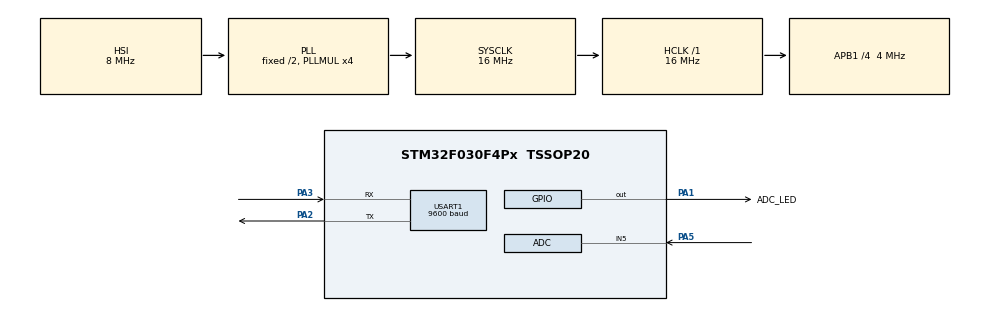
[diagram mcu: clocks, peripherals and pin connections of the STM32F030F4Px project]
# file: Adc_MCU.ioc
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ADC.ClockPrescaler=ADC_CLOCK_ASYNC_DIV1
ADC.ContinuousConvMode=DISABLE
ADC.DMAContinuousRequests=ENABLE
ADC.ExternalTrigConv=ADC_EXTERNALTRIGCONV_T3_TRGO
ADC.SamplingTime=ADC_SAMPLETIME_239CYCLES_5
Dma.ADC.0.Direction=DMA_PERIPH_TO_MEMORY
Dma.ADC.0.Instance=DMA1_Channel1
Dma.ADC.0.MemDataAlignment=DMA_MDATAALIGN_HALFWORD
Dma.ADC.0.MemInc=DMA_MINC_ENABLE
Dma.ADC.0.Mode=DMA_CIRCULAR
Dma.ADC.0.PeriphDataAlignment=DMA_PDATAALIGN_HALFWORD
Dma.ADC.0.PeriphInc=DMA_PINC_DISABLE
Dma.ADC.0.Priority=DMA_PRIORITY_MEDIUM
Dma.Request0=ADC
Mcu.Family=STM32F0
Mcu.Name=STM32F030F4Px
Mcu.Package=TSSOP20
NVIC.DMA1_Channel1_IRQn=true\:0\:0\:false\:false\:true\:false\:true
NVIC.TIM3_IRQn=true\:0\:0\:false\:false\:true\:true\:true
PA1.GPIO_Label=ADC_LED
PA1.Signal=GPIO_Output
PA13.Mode=Serial_Wire
PA13.Signal=SYS_SWDIO
PA14.Mode=Serial_Wire
PA14.Signal=SYS_SWCLK
PA2.Mode=Asynchronous
PA2.Signal=USART1_TX
PA3.Mode=Asynchronous
PA3.Signal=USART1_RX
PA5.Mode=IN5
PA5.Signal=ADC_IN5
ProjectManager.HeapSize=0x200
ProjectManager.StackSize=0x400
ProjectManager.TargetToolchain=STM32CubeIDE
RCC.AHBFreq_Value=16000000
RCC.APB1CLKDivider=RCC_HCLK_DIV4
RCC.APB1Freq_Value=4000000
RCC.APB1TimFreq_Value=8000000
RCC.HCLKFreq_Value=16000000
RCC.PLLMUL=RCC_PLL_MUL4
RCC.SYSCLKFreq_VALUE=16000000
RCC.SYSCLKSource=RCC_SYSCLKSOURCE_PLLCLK
TIM3.Period=1
TIM3.Prescaler=7999
TIM3.TIM_MasterOutputTrigger=TIM_TRGO_UPDATE
USART1.BaudRate=9600
USART1.Mode=MODE_TX
USART1.VirtualMode-Asynchronous=VM_ASYNC
VP_TIM3_VS_ClockSourceINT.Mode=Internal
board=custom

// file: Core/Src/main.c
/* USER CODE BEGIN Header */
/**
  ******************************************************************************
  * @file           : main.c
  * @brief          : Main program body
  ******************************************************************************
  * @attention
  *
  * Copyright (c) 2022 STMicroelectronics.
  * All rights reserved.
  *
  * This software is licensed under terms that can be found in the LICENSE file
  * in the root directory of this software component.
  * If no LICENSE file comes with this software, it is provided AS-IS.
  *
  ******************************************************************************
  */
/* USER CODE END Header */
#include "main.h"

/* USER CODE BEGIN Includes */
#include <adc.h>
#include <uart.h>
/* USER CODE END Includes */

ADC_HandleTypeDef hadc;
DMA_HandleTypeDef hdma_adc;

TIM_HandleTypeDef htim3;

UART_HandleTypeDef huart1;

/* USER CODE BEGIN PV */
extern float adc_value;
/* USER CODE END PV */

void SystemClock_Config(void);
static void MX_GPIO_Init(void);
static void MX_DMA_Init(void);
static void MX_ADC_Init(void);
static void MX_TIM3_Init(void);
static void MX_USART1_UART_Init(void);

int main(void)
{

  /* MCU Configuration--------------------------------------------------------*/

  /* Reset of all peripherals, Initializes the Flash interface and the Systick. */
  HAL_Init();

  /* Configure the system clock */
  SystemClock_Config();

  /* Initialize all configured peripherals */
  MX_GPIO_Init();
  MX_DMA_Init();
  MX_ADC_Init();
  MX_TIM3_Init();
  MX_USART1_UART_Init();
  /* USER CODE BEGIN 2 */
  Start_Adc();
  /* USER CODE END 2 */

  /* Infinite loop */
  /* USER CODE BEGIN WHILE */
  while (1)
  {
	  Send_Adc(adc_value);
	  HAL_Delay(200);

    /* USER CODE END WHILE */

  }
}

void SystemClock_Config(void)
{
  RCC_OscInitTypeDef RCC_OscInitStruct = {0};
  RCC_ClkInitTypeDef RCC_ClkInitStruct = {0};
  RCC_PeriphCLKInitTypeDef PeriphClkInit = {0};

  /** Initializes the RCC Oscillators according to the specified parameters
  * in the RCC_OscInitTypeDef structure.
  */
  RCC_OscInitStruct.OscillatorType = RCC_OSCILLATORTYPE_HSI|RCC_OSCILLATORTYPE_HSI14;
  RCC_OscInitStruct.HSIState = RCC_HSI_ON;
  RCC_OscInitStruct.HSI14State = RCC_HSI14_ON;
  RCC_OscInitStruct.HSICalibrationValue = RCC_HSICALIBRATION_DEFAULT;
  RCC_OscInitStruct.HSI14CalibrationValue = 16;
  RCC_OscInitStruct.PLL.PLLState = RCC_PLL_ON;
  RCC_OscInitStruct.PLL.PLLSource = RCC_PLLSOURCE_HSI;
  RCC_OscInitStruct.PLL.PLLMUL = RCC_PLL_MUL4;
  RCC_OscInitStruct.PLL.PREDIV = RCC_PREDIV_DIV1;
  if (HAL_RCC_OscConfig(&RCC_OscInitStruct) != HAL_OK)
  {
    Error_Handler();
  }
  /** Initializes the CPU, AHB and APB buses clocks
  */
  RCC_ClkInitStruct.ClockType = RCC_CLOCKTYPE_HCLK|RCC_CLOCKTYPE_SYSCLK
                              |RCC_CLOCKTYPE_PCLK1;
  RCC_ClkInitStruct.SYSCLKSource = RCC_SYSCLKSOURCE_PLLCLK;
  RCC_ClkInitStruct.AHBCLKDivider = RCC_SYSCLK_DIV1;
  RCC_ClkInitStruct.APB1CLKDivider = RCC_HCLK_DIV4;

  if (HAL_RCC_ClockConfig(&RCC_ClkInitStruct, FLASH_LATENCY_0) != HAL_OK)
  {
    Error_Handler();
  }
  PeriphClkInit.PeriphClockSelection = RCC_PERIPHCLK_USART1;
  PeriphClkInit.Usart1ClockSelection = RCC_USART1CLKSOURCE_PCLK1;
  if (HAL_RCCEx_PeriphCLKConfig(&PeriphClkInit) != HAL_OK)
  {
    Error_Handler();
  }
}

static void MX_ADC_Init(void)
{

  ADC_ChannelConfTypeDef sConfig = {0};

  /** Configure the global features of the ADC (Clock, Resolution, Data Alignment and number of conversion)
  */
  hadc.Instance = ADC1;
  hadc.Init.ClockPrescaler = ADC_CLOCK_ASYNC_DIV1;
  hadc.Init.Resolution = ADC_RESOLUTION_12B;
  hadc.Init.DataAlign = ADC_DATAALIGN_RIGHT;
  hadc.Init.ScanConvMode = ADC_SCAN_DIRECTION_FORWARD;
  hadc.Init.EOCSelection = ADC_EOC_SINGLE_CONV;
  hadc.Init.LowPowerAutoWait = DISABLE;
  hadc.Init.LowPowerAutoPowerOff = DISABLE;
  hadc.Init.ContinuousConvMode = DISABLE;
  hadc.Init.DiscontinuousConvMode = DISABLE;
  hadc.Init.ExternalTrigConv = ADC_EXTERNALTRIGCONV_T3_TRGO;
  hadc.Init.ExternalTrigConvEdge = ADC_EXTERNALTRIGCONVEDGE_RISING;
  hadc.Init.DMAContinuousRequests = ENABLE;
  hadc.Init.Overrun = ADC_OVR_DATA_PRESERVED;
  if (HAL_ADC_Init(&hadc) != HAL_OK)
  {
    Error_Handler();
  }
  /** Configure for the selected ADC regular channel to be converted.
  */
  sConfig.Channel = ADC_CHANNEL_5;
  sConfig.Rank = ADC_RANK_CHANNEL_NUMBER;
  sConfig.SamplingTime = ADC_SAMPLETIME_239CYCLES_5;
  if (HAL_ADC_ConfigChannel(&hadc, &sConfig) != HAL_OK)
  {
    Error_Handler();
  }

}

static void MX_TIM3_Init(void)
{

  TIM_ClockConfigTypeDef sClockSourceConfig = {0};
  TIM_MasterConfigTypeDef sMasterConfig = {0};

  htim3.Instance = TIM3;
  htim3.Init.Prescaler = 7999;
  htim3.Init.CounterMode = TIM_COUNTERMODE_UP;
  htim3.Init.Period = 1;
  htim3.Init.ClockDivision = TIM_CLOCKDIVISION_DIV1;
  htim3.Init.AutoReloadPreload = TIM_AUTORELOAD_PRELOAD_DISABLE;
  if (HAL_TIM_Base_Init(&htim3) != HAL_OK)
  {
    Error_Handler();
  }
  sClockSourceConfig.ClockSource = TIM_CLOCKSOURCE_INTERNAL;
  if (HAL_TIM_ConfigClockSource(&htim3, &sClockSourceConfig) != HAL_OK)
  {
    Error_Handler();
  }
  sMasterConfig.MasterOutputTrigger = TIM_TRGO_UPDATE;
  sMasterConfig.MasterSlaveMode = TIM_MASTERSLAVEMODE_DISABLE;
  if (HAL_TIMEx_MasterConfigSynchronization(&htim3, &sMasterConfig) != HAL_OK)
  {
    Error_Handler();
  }

}

static void MX_USART1_UART_Init(void)
{

  huart1.Instance = USART1;
  huart1.Init.BaudRate = 9600;
  huart1.Init.WordLength = UART_WORDLENGTH_8B;
  huart1.Init.StopBits = UART_STOPBITS_1;
  huart1.Init.Parity = UART_PARITY_NONE;
  huart1.Init.Mode = UART_MODE_TX;
  huart1.Init.HwFlowCtl = UART_HWCONTROL_NONE;
  huart1.Init.OverSampling = UART_OVERSAMPLING_16;
  huart1.Init.OneBitSampling = UART_ONE_BIT_SAMPLE_DISABLE;
  huart1.AdvancedInit.AdvFeatureInit = UART_ADVFEATURE_NO_INIT;
  if (HAL_UART_Init(&huart1) != HAL_OK)
  {
    Error_Handler();
  }

}

static void MX_DMA_Init(void)
{

  /* DMA controller clock enable */
  __HAL_RCC_DMA1_CLK_ENABLE();

  /* DMA interrupt init */
  /* DMA1_Channel1_IRQn interrupt configuration */
  HAL_NVIC_SetPriority(DMA1_Channel1_IRQn, 0, 0);
  HAL_NVIC_EnableIRQ(DMA1_Channel1_IRQn);

}

static void MX_GPIO_Init(void)
{
  GPIO_InitTypeDef GPIO_InitStruct = {0};

  /* GPIO Ports Clock Enable */
  __HAL_RCC_GPIOA_CLK_ENABLE();

  /*Configure GPIO pin Output Level */
  HAL_GPIO_WritePin(ADC_LED_GPIO_Port, ADC_LED_Pin, GPIO_PIN_RESET);

  /*Configure GPIO pin : ADC_LED_Pin */
  GPIO_InitStruct.Pin = ADC_LED_Pin;
  GPIO_InitStruct.Mode = GPIO_MODE_OUTPUT_PP;
  GPIO_InitStruct.Pull = GPIO_NOPULL;
  GPIO_InitStruct.Speed = GPIO_SPEED_FREQ_LOW;
  HAL_GPIO_Init(ADC_LED_GPIO_Port, &GPIO_InitStruct);

}

void Error_Handler(void)
{
  __disable_irq();
  while (1)
  {
  }
}
